# MCXN947_cm33_core0 register map
Vendor: nxp.com; File version: 1.0
CPU: CM33 r2p0, little endian, MPU, FPU, VTOR, 3 interrupt priority bits
Registers are 32-bit, read-write, reset 0x0 unless marked. A register's access mark holds for its fields unless they carry their own. Offsets are from the block's base; [hi:lo] are bit positions; {n}, {i} and the like mark numbered series.

## PDM — MICFIL
Base 0x4010C000
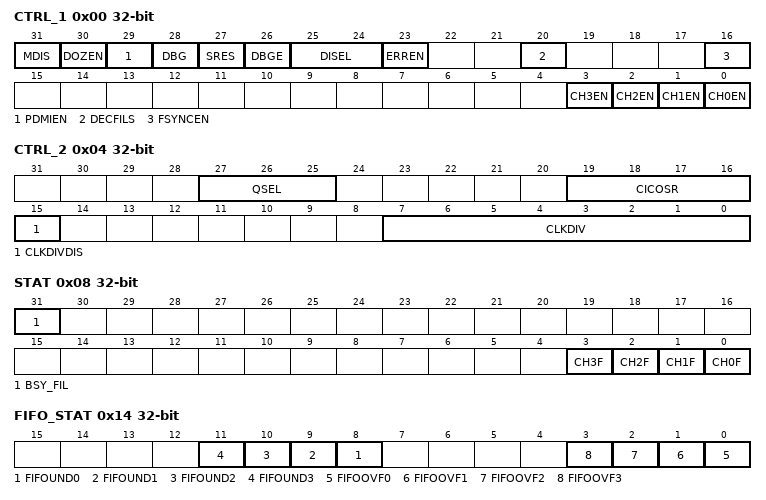
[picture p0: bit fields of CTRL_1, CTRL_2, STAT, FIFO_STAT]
0x00 CTRL_1 — MICFIL Control 1
  [31] MDIS — Module Disable
    0=Normal mode; 1=low_leakage (DLL mode)
  [30] DOZEN — Doze Enable
  [29] PDMIEN — MICFIL Enable
    0=stopped (Stops MICFIL operation); 1=started (Starts MICFIL operation)
  [28] DBG — Debug Mode
    0=normal; 1=debug
  [27] SRES — Software Reset
    0=no_action; 1=sw_reset (Software reset)
  [26] DBGE — Module Enable in Debug
    0=disabled (Disables after completing the current frame); 1=enabled (Enables operation)
  [25:24] DISEL — DMA Interrupt Selection
    0=all_disabled (Disables DMA and interrupt requests); 1=dmareq_enabled (Enables DMA requests); 2=intreq_enabled (Enables interrupt requests)
  [23] ERREN — Error Interruption Enable
    0=disabled (Disables); 1=enabled (Enables)
  [20] DECFILS — Decimation Filter Enable in Stop
    0=Stops decimation filter; 1=run (Keeps decimation filter running)
  [16] FSYNCEN — Frame Synchronization Enable
    0=DISABLE (Disables); 1=ENABLE (Enables)
  [n] CH{n}EN (n=0..3) — Channel {n} Enable
0x04 CTRL_2 — MICFIL Control 2
  [27:25] QSEL — Quality Mode
    0=mq_mode (Medium-Quality mode); 1=hq_mode (High-Quality mode); 4=vlq2_mode (Very-Low-Quality 2 mode); 5=vlq1_mode (Very-Low-Quality 1 mode); 6=vlq0_mode (Very-Low-Quality 0 mode); 7=lq_mode (Low-Quality mode)
  [19:16] CICOSR — CIC Decimation Rate
  [15] CLKDIVDIS — Clock Divider Disable
    0=ENABLE (Enables); 1=DISABLE (Disables)
  [7:0] CLKDIV — Clock Divider
0x08 STAT — MICFIL Status
  [31] BSY_FIL ro — Busy Flag
    0=stopped (MICFIL is stopped); 1=running (MICFIL is running)
  [n] CH{n}F write-1-clears (n=0..3) — Channel {n} Output Data Flag
    0=wm_notreached (Not surpassed); 1=wm_reached (Surpassed)
0x10 FIFO_CTRL reset 0xF — MICFIL FIFO Control
  [3:0] FIFOWMK — FIFO Watermark Control
0x14 FIFO_STAT write-1-clears — MICFIL FIFO Status
  [n+8] FIFOUND{n} write-1-clears (n=0..3) — FIFO Underflow Exception Flag for Channel {n}
    0=No exception by FIFO underflow; 1=Exception by FIFO underflow
  [n] FIFOOVF{n} write-1-clears (n=0..3) — FIFO Overflow Exception Flag for Channel {n}
    0=No exception by FIFO overflow; 1=Exception by FIFO overflow
{0x24+4i} DATACH[{i}] (i=0..3) ro — MICFIL Output Result
  [31:0] DATA — Channel n Data
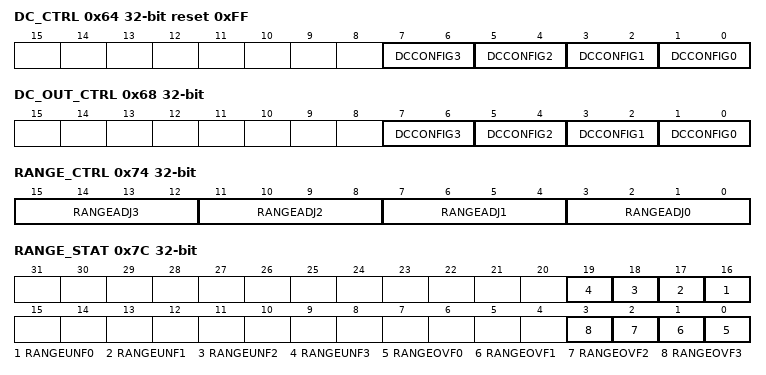
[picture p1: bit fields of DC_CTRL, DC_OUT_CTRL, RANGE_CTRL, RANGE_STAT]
0x64 DC_CTRL ro reset 0xFF — MICFIL DC Remover Control
  [all] fields
    0=dc_rem_20Hz (20 Hz (PDM_CLK = 3.072 MHz)); 1=dc_rem_13p3Hz (13.3 Hz (PDM_CLK = 3.072 MHz)); 2=dc_rem_40Hz (40 Hz (PDM_CLK = 3.072 MHz)); 3=dc_rem_bypass (DC remover is bypassed)
  [2n+1:2n] DCCONFIG{n} (n=0..3) — Channel {n} DC Remover Configuration
0x68 DC_OUT_CTRL — MICFIL Output DC Remover Control
  [all] fields
    0=dc_rem_20Hz (20 Hz (FS = 48 kHz)); 1=dc_rem_13p3Hz (13.3 Hz (FS = 48 kHz)); 2=dc_rem_40Hz (40 Hz (FS = 48 kHz)); 3=dc_rem_bypassed (DC remover is bypassed)
  [2n+1:2n] DCCONFIG{n} (n=0..3) — Channel {n} DC Remover Configuration
0x74 RANGE_CTRL — MICFIL Range Control
  [4n+3:4n] RANGEADJ{n} (n=0..3) — Channel {n} Range Adjustment
0x7C RANGE_STAT write-1-clears — MICFIL Range Status
  [n+16] RANGEUNF{n} write-1-clears (n=0..3) — Channel {n} Range Underflow Error Flag
    0=No exception by range underflow; 1=Exception by range underflow
  [n] RANGEOVF{n} write-1-clears (n=0..3) — Channel {n} Range Overflow Error Flag
    0=No exception by range overflow; 1=Exception by range overflow
0x80 FSYNC_CTRL — Frame Synchronization Control
  [31:0] FSYNCLEN — Frame Synchronization Window Length
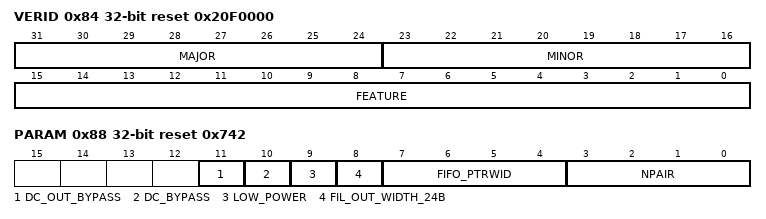
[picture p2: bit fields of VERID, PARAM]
0x84 VERID ro reset 0x20F0000 — Version ID
  [31:24] MAJOR — Major Version Number
  [23:16] MINOR — Minor Version Number
  [15:0] FEATURE — Feature Specification Number
0x88 PARAM ro reset 0x742 — Parameter
  [11] DC_OUT_BYPASS — Output DC Remover Bypass
    0=DCACTIVE (Active); 1=DCBYPASSED (Disabled)
  [10] DC_BYPASS — Input DC Remover Bypass
    0=DCACTIVE (Active); 1=DCBYPASSED (Disabled)
  [9] LOW_POWER — Low-Power Decimation Filter
    0=DISABLE (Disables); 1=ENABLE (Enables)
  [8] FIL_OUT_WIDTH_24B — Filter Output Width
    0=WID16B (16 bits); 1=WID24B (24 bits)
  [7:4] FIFO_PTRWID — FIFO Pointer Width
  [3:0] NPAIR — Number of Microphone Pairs
